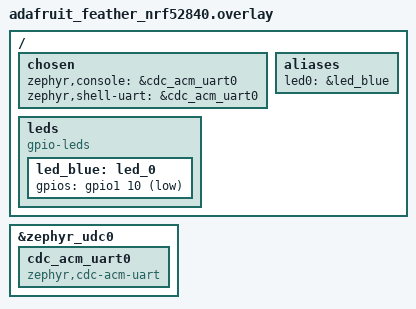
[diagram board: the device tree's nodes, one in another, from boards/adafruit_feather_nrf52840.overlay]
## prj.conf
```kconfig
CONFIG_LOG=y
CONFIG_LOG_BACKEND_UART=y

CONFIG_GPIO=y
```

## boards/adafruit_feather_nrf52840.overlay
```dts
/ {
    chosen {
        zephyr,console = &cdc_acm_uart0;
        zephyr,shell-uart = &cdc_acm_uart0;
    };

   	aliases {
   		led0 = &led_blue;
   	};

   	leds {
   		compatible = "gpio-leds";
   		led_blue: led_0 {
   			gpios = <&gpio1 10 GPIO_ACTIVE_LOW>;
                };
   	};
};

&zephyr_udc0 {
    cdc_acm_uart0: cdc_acm_uart0 {
        compatible = "zephyr,cdc-acm-uart";
    };
};
```

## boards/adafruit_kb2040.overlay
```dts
/ {
    chosen {
        zephyr,console = &cdc_acm_uart0;
        zephyr,shell-uart = &cdc_acm_uart0;
    };

    aliases {
        led0 = &led_blue;
    };

    leds {
        compatible = "gpio-leds";
        led_blue: led_0 {
            gpios = <&gpio0 9 GPIO_ACTIVE_LOW>;
                };
    };

};

&zephyr_udc0 {
    cdc_acm_uart0: cdc_acm_uart0 {
        compatible = "zephyr,cdc-acm-uart";
    };
};
```

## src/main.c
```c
/*
 * Copyright (c) 2016 Intel Corporation
 *
 * SPDX-License-Identifier: Apache-2.0
 */

#include <zephyr/kernel.h>
#include <zephyr/drivers/gpio.h>
#include <zephyr/logging/log.h>

LOG_MODULE_REGISTER(main);

/* 1000 msec = 1 sec */
#define SLEEP_TIME_MS   1000

/* The devicetree node identifier for the "led0" alias. */
#define LED0_NODE DT_ALIAS(led0)

/*
 * A build error on this line means your board is unsupported.
 * See the sample documentation for information on how to fix this.
 */
static const struct gpio_dt_spec led = GPIO_DT_SPEC_GET(LED0_NODE, gpios);

void main(void)
{
	int ret;

	LOG_INF("Starting demo");

	if (!gpio_is_ready_dt(&led)) {
		return;
	}

	ret = gpio_pin_configure_dt(&led, GPIO_OUTPUT_ACTIVE);
	if (ret < 0) {
		return;
	}


	while (1) {
		LOG_INF("Blinking");
		ret = gpio_pin_toggle_dt(&led);
		if (ret < 0) {
			return;
		}
		k_msleep(SLEEP_TIME_MS);
	}
}
```
